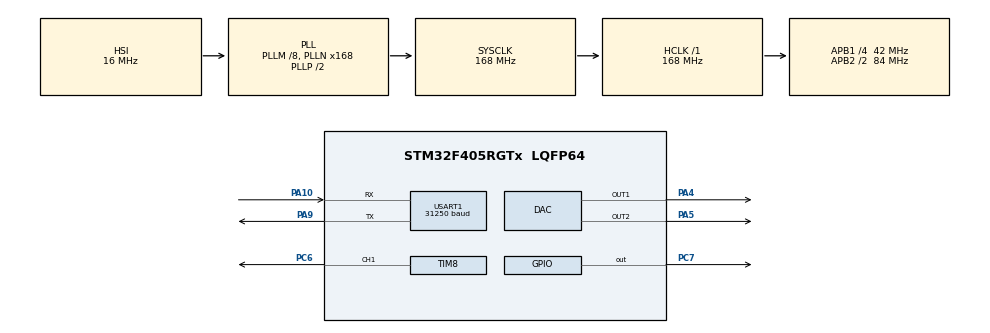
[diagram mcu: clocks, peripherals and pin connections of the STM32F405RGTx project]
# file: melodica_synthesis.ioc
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DAC.DAC_Trigger=DAC_TRIGGER_T8_TRGO
DAC.DAC_Trigger2=DAC_TRIGGER_T8_TRGO
Dma.DAC1.1.Direction=DMA_MEMORY_TO_PERIPH
Dma.DAC1.1.FIFOMode=DMA_FIFOMODE_DISABLE
Dma.DAC1.1.Instance=DMA1_Stream5
Dma.DAC1.1.MemDataAlignment=DMA_MDATAALIGN_HALFWORD
Dma.DAC1.1.MemInc=DMA_MINC_ENABLE
Dma.DAC1.1.Mode=DMA_CIRCULAR
Dma.DAC1.1.PeriphDataAlignment=DMA_PDATAALIGN_HALFWORD
Dma.DAC1.1.PeriphInc=DMA_PINC_DISABLE
Dma.DAC1.1.Priority=DMA_PRIORITY_HIGH
Dma.DAC2.0.Direction=DMA_MEMORY_TO_PERIPH
Dma.DAC2.0.FIFOMode=DMA_FIFOMODE_DISABLE
Dma.DAC2.0.Instance=DMA1_Stream6
Dma.DAC2.0.MemDataAlignment=DMA_MDATAALIGN_HALFWORD
Dma.DAC2.0.MemInc=DMA_MINC_ENABLE
Dma.DAC2.0.Mode=DMA_CIRCULAR
Dma.DAC2.0.PeriphDataAlignment=DMA_PDATAALIGN_HALFWORD
Dma.DAC2.0.PeriphInc=DMA_PINC_DISABLE
Dma.DAC2.0.Priority=DMA_PRIORITY_HIGH
Dma.Request0=DAC2
Dma.Request1=DAC1
Mcu.Family=STM32F4
Mcu.Name=STM32F405RGTx
Mcu.Package=LQFP64
NVIC.DMA1_Stream5_IRQn=true\:0\:0\:false\:false\:true\:false\:true\:true
NVIC.DMA1_Stream6_IRQn=true\:0\:0\:false\:false\:true\:false\:true\:true
NVIC.PriorityGroup=NVIC_PRIORITYGROUP_4
NVIC.USART1_IRQn=true\:0\:0\:false\:false\:true\:true\:true\:true
PA10.Mode=Asynchronous
PA10.Signal=USART1_RX
PA13.Signal=SYS_JTMS-SWDIO
PA14.Signal=SYS_JTCK-SWCLK
PA4.Signal=COMP_DAC1_group
PA5.Signal=COMP_DAC2_group
PA9.Mode=Asynchronous
PA9.Signal=USART1_TX
PC6.Signal=S_TIM8_CH1
PC7.Signal=GPIO_Output
ProjectManager.HeapSize=0x200
ProjectManager.StackSize=0x400
ProjectManager.TargetToolchain=STM32CubeIDE
RCC.48MHZClocksFreq_Value=84000000
RCC.AHBFreq_Value=168000000
RCC.APB1CLKDivider=RCC_HCLK_DIV4
RCC.APB1Freq_Value=42000000
RCC.APB1TimFreq_Value=84000000
RCC.APB2CLKDivider=RCC_HCLK_DIV2
RCC.APB2Freq_Value=84000000
RCC.APB2TimFreq_Value=168000000
RCC.CortexFreq_Value=168000000
RCC.HCLKFreq_Value=168000000
RCC.HSE_VALUE=25000000
RCC.HSI_VALUE=16000000
RCC.LSE_VALUE=32768
RCC.PLLM=8
RCC.PLLN=168
RCC.SYSCLKFreq_VALUE=168000000
RCC.SYSCLKSource=RCC_SYSCLKSOURCE_PLLCLK
RCC.VCOOutputFreq_Value=336000000
SH.COMP_DAC1_group.0=DAC_OUT1,DAC_OUT1
SH.COMP_DAC2_group.0=DAC_OUT2,DAC_OUT2
SH.S_TIM8_CH1.0=TIM8_CH1,PWM Generation1 CH1
TIM2.Period=99
TIM2.Prescaler=1680-1
TIM2.TIM_MasterOutputTrigger=TIM_TRGO_UPDATE
TIM8.Channel-PWM\ Generation1\ CH1=TIM_CHANNEL_1
TIM8.Period=4000-1
TIM8.TIM_MasterOutputTrigger=TIM_TRGO_UPDATE
USART1.BaudRate=31250
USART1.VirtualMode=VM_ASYNC
VP_TIM2_VS_ClockSourceINT.Mode=Internal
board=custom

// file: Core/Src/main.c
/* USER CODE BEGIN Header */
/**
  ******************************************************************************
  * @file           : main.c
  * @brief          : Main program body
  ******************************************************************************
  * @attention
  *
  * Copyright (c) 2025 STMicroelectronics.
  * All rights reserved.
  *
  * This software is licensed under terms that can be found in the LICENSE file
  * in the root directory of this software component.
  * If no LICENSE file comes with this software, it is provided AS-IS.
  *
  ******************************************************************************
  */
#include "audio.h"
/* USER CODE END Header */
#include "main.h"

/* USER CODE BEGIN Includes */
#include "midi.h"
#include "looper.h"
/* USER CODE END Includes */

DAC_HandleTypeDef hdac;
DMA_HandleTypeDef hdma_dac2;
DMA_HandleTypeDef hdma_dac1;

TIM_HandleTypeDef htim2;
TIM_HandleTypeDef htim8;

UART_HandleTypeDef huart1;

void SystemClock_Config(void);
static void MX_GPIO_Init(void);
static void MX_DMA_Init(void);
static void MX_DAC_Init(void);
static void MX_TIM8_Init(void);
static void MX_USART1_UART_Init(void);
static void MX_TIM2_Init(void);

int main(void)
{

  /* MCU Configuration--------------------------------------------------------*/

  /* Reset of all peripherals, Initializes the Flash interface and the Systick. */
  HAL_Init();

  /* Configure the system clock */
  SystemClock_Config();

  /* Initialize all configured peripherals */
  MX_GPIO_Init();
  MX_DMA_Init();
  MX_DAC_Init();
  MX_TIM8_Init();
  MX_USART1_UART_Init();
  MX_TIM2_Init();
  /* USER CODE BEGIN 2 */
  MIDI_Init(&note_callbk);
  LOOPER_INIT();
  HAL_TIM_Base_Start(&htim2);

  // For debugging: - good use in stm32f4xx_it.c it can be set to go high when hard fault occurs
  HAL_GPIO_WritePin(GPIOC, GPIO_PIN_7, 0);

  audio_signal_init(&htim8, &hdac);

  /* USER CODE END 2 */

  /* Infinite loop */
  /* USER CODE BEGIN WHILE */
  while (1)
  {
	  audio_signal_loop_tick();
	  looper_tick();
    /* USER CODE END WHILE */

  }
}

void SystemClock_Config(void)
{
  RCC_OscInitTypeDef RCC_OscInitStruct = {0};
  RCC_ClkInitTypeDef RCC_ClkInitStruct = {0};

  /** Configure the main internal regulator output voltage
  */
  __HAL_RCC_PWR_CLK_ENABLE();
  __HAL_PWR_VOLTAGESCALING_CONFIG(PWR_REGULATOR_VOLTAGE_SCALE1);

  /** Initializes the RCC Oscillators according to the specified parameters
  * in the RCC_OscInitTypeDef structure.
  */
  RCC_OscInitStruct.OscillatorType = RCC_OSCILLATORTYPE_HSI;
  RCC_OscInitStruct.HSIState = RCC_HSI_ON;
  RCC_OscInitStruct.HSICalibrationValue = RCC_HSICALIBRATION_DEFAULT;
  RCC_OscInitStruct.PLL.PLLState = RCC_PLL_ON;
  RCC_OscInitStruct.PLL.PLLSource = RCC_PLLSOURCE_HSI;
  RCC_OscInitStruct.PLL.PLLM = 8;
  RCC_OscInitStruct.PLL.PLLN = 168;
  RCC_OscInitStruct.PLL.PLLP = RCC_PLLP_DIV2;
  RCC_OscInitStruct.PLL.PLLQ = 4;
  if (HAL_RCC_OscConfig(&RCC_OscInitStruct) != HAL_OK)
  {
    Error_Handler();
  }

  /** Initializes the CPU, AHB and APB buses clocks
  */
  RCC_ClkInitStruct.ClockType = RCC_CLOCKTYPE_HCLK|RCC_CLOCKTYPE_SYSCLK
                              |RCC_CLOCKTYPE_PCLK1|RCC_CLOCKTYPE_PCLK2;
  RCC_ClkInitStruct.SYSCLKSource = RCC_SYSCLKSOURCE_PLLCLK;
  RCC_ClkInitStruct.AHBCLKDivider = RCC_SYSCLK_DIV1;
  RCC_ClkInitStruct.APB1CLKDivider = RCC_HCLK_DIV4;
  RCC_ClkInitStruct.APB2CLKDivider = RCC_HCLK_DIV2;

  if (HAL_RCC_ClockConfig(&RCC_ClkInitStruct, FLASH_LATENCY_5) != HAL_OK)
  {
    Error_Handler();
  }
}

static void MX_DAC_Init(void)
{

  DAC_ChannelConfTypeDef sConfig = {0};

  /** DAC Initialization
  */
  hdac.Instance = DAC;
  if (HAL_DAC_Init(&hdac) != HAL_OK)
  {
    Error_Handler();
  }

  /** DAC channel OUT1 config
  */
  sConfig.DAC_Trigger = DAC_TRIGGER_T8_TRGO;
  sConfig.DAC_OutputBuffer = DAC_OUTPUTBUFFER_ENABLE;
  if (HAL_DAC_ConfigChannel(&hdac, &sConfig, DAC_CHANNEL_1) != HAL_OK)
  {
    Error_Handler();
  }

  /** DAC channel OUT2 config
  */
  if (HAL_DAC_ConfigChannel(&hdac, &sConfig, DAC_CHANNEL_2) != HAL_OK)
  {
    Error_Handler();
  }

}

static void MX_TIM2_Init(void)
{

  TIM_ClockConfigTypeDef sClockSourceConfig = {0};
  TIM_MasterConfigTypeDef sMasterConfig = {0};

  htim2.Instance = TIM2;
  htim2.Init.Prescaler = 1680-1;
  htim2.Init.CounterMode = TIM_COUNTERMODE_UP;
  htim2.Init.Period = 199;
  htim2.Init.ClockDivision = TIM_CLOCKDIVISION_DIV1;
  htim2.Init.AutoReloadPreload = TIM_AUTORELOAD_PRELOAD_DISABLE;
  if (HAL_TIM_Base_Init(&htim2) != HAL_OK)
  {
    Error_Handler();
  }
  sClockSourceConfig.ClockSource = TIM_CLOCKSOURCE_INTERNAL;
  if (HAL_TIM_ConfigClockSource(&htim2, &sClockSourceConfig) != HAL_OK)
  {
    Error_Handler();
  }
  sMasterConfig.MasterOutputTrigger = TIM_TRGO_UPDATE;
  sMasterConfig.MasterSlaveMode = TIM_MASTERSLAVEMODE_DISABLE;
  if (HAL_TIMEx_MasterConfigSynchronization(&htim2, &sMasterConfig) != HAL_OK)
  {
    Error_Handler();
  }

}

static void MX_TIM8_Init(void)
{

  TIM_MasterConfigTypeDef sMasterConfig = {0};
  TIM_OC_InitTypeDef sConfigOC = {0};
  TIM_BreakDeadTimeConfigTypeDef sBreakDeadTimeConfig = {0};

  htim8.Instance = TIM8;
  htim8.Init.Prescaler = 0;
  htim8.Init.CounterMode = TIM_COUNTERMODE_UP;
  htim8.Init.Period = 4000-1;
  htim8.Init.ClockDivision = TIM_CLOCKDIVISION_DIV1;
  htim8.Init.RepetitionCounter = 0;
  htim8.Init.AutoReloadPreload = TIM_AUTORELOAD_PRELOAD_DISABLE;
  if (HAL_TIM_PWM_Init(&htim8) != HAL_OK)
  {
    Error_Handler();
  }
  sMasterConfig.MasterOutputTrigger = TIM_TRGO_UPDATE;
  sMasterConfig.MasterSlaveMode = TIM_MASTERSLAVEMODE_DISABLE;
  if (HAL_TIMEx_MasterConfigSynchronization(&htim8, &sMasterConfig) != HAL_OK)
  {
    Error_Handler();
  }
  sConfigOC.OCMode = TIM_OCMODE_PWM1;
  sConfigOC.Pulse = 0;
  sConfigOC.OCPolarity = TIM_OCPOLARITY_HIGH;
  sConfigOC.OCNPolarity = TIM_OCNPOLARITY_HIGH;
  sConfigOC.OCFastMode = TIM_OCFAST_DISABLE;
  sConfigOC.OCIdleState = TIM_OCIDLESTATE_RESET;
  sConfigOC.OCNIdleState = TIM_OCNIDLESTATE_RESET;
  if (HAL_TIM_PWM_ConfigChannel(&htim8, &sConfigOC, TIM_CHANNEL_1) != HAL_OK)
  {
    Error_Handler();
  }
  sBreakDeadTimeConfig.OffStateRunMode = TIM_OSSR_DISABLE;
  sBreakDeadTimeConfig.OffStateIDLEMode = TIM_OSSI_DISABLE;
  sBreakDeadTimeConfig.LockLevel = TIM_LOCKLEVEL_OFF;
  sBreakDeadTimeConfig.DeadTime = 0;
  sBreakDeadTimeConfig.BreakState = TIM_BREAK_DISABLE;
  sBreakDeadTimeConfig.BreakPolarity = TIM_BREAKPOLARITY_HIGH;
  sBreakDeadTimeConfig.AutomaticOutput = TIM_AUTOMATICOUTPUT_DISABLE;
  if (HAL_TIMEx_ConfigBreakDeadTime(&htim8, &sBreakDeadTimeConfig) != HAL_OK)
  {
    Error_Handler();
  }
  HAL_TIM_MspPostInit(&htim8);

}

static void MX_USART1_UART_Init(void)
{

  huart1.Instance = USART1;
  huart1.Init.BaudRate = 31250;
  huart1.Init.WordLength = UART_WORDLENGTH_8B;
  huart1.Init.StopBits = UART_STOPBITS_1;
  huart1.Init.Parity = UART_PARITY_NONE;
  huart1.Init.Mode = UART_MODE_TX_RX;
  huart1.Init.HwFlowCtl = UART_HWCONTROL_NONE;
  huart1.Init.OverSampling = UART_OVERSAMPLING_16;
  if (HAL_UART_Init(&huart1) != HAL_OK)
  {
    Error_Handler();
  }

}

static void MX_DMA_Init(void)
{

  /* DMA controller clock enable */
  __HAL_RCC_DMA1_CLK_ENABLE();

  /* DMA interrupt init */
  /* DMA1_Stream5_IRQn interrupt configuration */
  HAL_NVIC_SetPriority(DMA1_Stream5_IRQn, 0, 0);
  HAL_NVIC_EnableIRQ(DMA1_Stream5_IRQn);
  /* DMA1_Stream6_IRQn interrupt configuration */
  HAL_NVIC_SetPriority(DMA1_Stream6_IRQn, 0, 0);
  HAL_NVIC_EnableIRQ(DMA1_Stream6_IRQn);

}

static void MX_GPIO_Init(void)
{
  GPIO_InitTypeDef GPIO_InitStruct = {0};

  /* GPIO Ports Clock Enable */
  __HAL_RCC_GPIOA_CLK_ENABLE();
  __HAL_RCC_GPIOC_CLK_ENABLE();

  /*Configure GPIO pin Output Level */
  HAL_GPIO_WritePin(GPIOC, GPIO_PIN_7, GPIO_PIN_RESET);

  /*Configure GPIO pin : PC7 */
  GPIO_InitStruct.Pin = GPIO_PIN_7;
  GPIO_InitStruct.Mode = GPIO_MODE_OUTPUT_PP;
  GPIO_InitStruct.Pull = GPIO_NOPULL;
  GPIO_InitStruct.Speed = GPIO_SPEED_FREQ_LOW;
  HAL_GPIO_Init(GPIOC, &GPIO_InitStruct);

}

void Error_Handler(void)
{
  __disable_irq();
  while (1)
  {
  }
}
